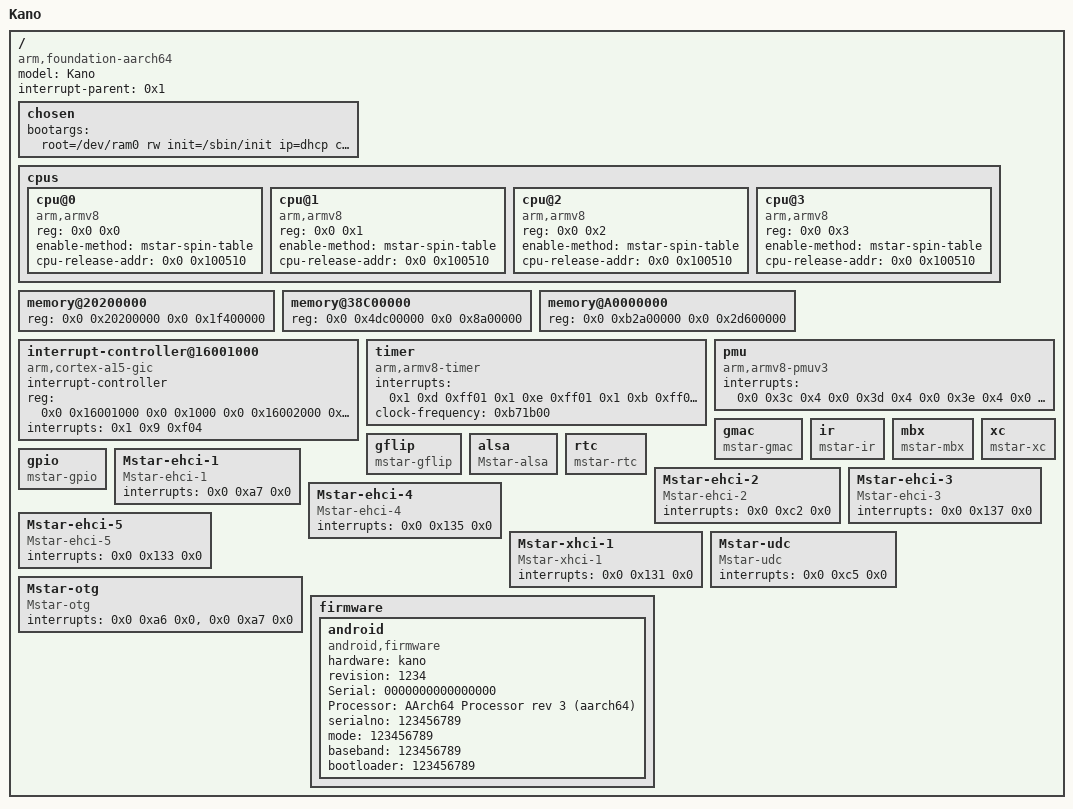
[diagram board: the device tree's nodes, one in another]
/dts-v1/;

/ {
	model = "Kano";
	compatible = "arm,foundation-aarch64", "arm,kano";
	interrupt-parent = <0x1>;
	#address-cells = <0x2>;
	#size-cells = <0x2>;

	chosen {
		bootargs = "root=/dev/ram0 rw init=/sbin/init ip=dhcp console=ttyS0,115200,LX_MEM=0x02000000 CMA0=mali0,miu=0,hid=16,sz=0x19000000 CMA1=mali1,miu=1,hid=17,sz=0x5400000 CORE_DUMP_PATH=/mnt/usb/core_dump.%%p.gz";
	};

	cpus {
		#address-cells = <0x2>;
		#size-cells = <0x0>;

		cpu@0 {
			device_type = "cpu";
			compatible = "arm,armv8";
			reg = <0x0 0x0>;
			enable-method = "mstar-spin-table";
			cpu-release-addr = <0x0 0x100510>;
		};

		cpu@1 {
			device_type = "cpu";
			compatible = "arm,armv8";
			reg = <0x0 0x1>;
			enable-method = "mstar-spin-table";
			cpu-release-addr = <0x0 0x100510>;
		};

		cpu@2 {
			device_type = "cpu";
			compatible = "arm,armv8";
			reg = <0x0 0x2>;
			enable-method = "mstar-spin-table";
			cpu-release-addr = <0x0 0x100510>;
		};

		cpu@3 {
			device_type = "cpu";
			compatible = "arm,armv8";
			reg = <0x0 0x3>;
			enable-method = "mstar-spin-table";
			cpu-release-addr = <0x0 0x100510>;
		};
	};

	memory@20200000 {
		device_type = "memory";
		reg = <0x0 0x20200000 0x0 0x1f400000>;
	};

	memory@38C00000 {
		device_type = "memory";
		reg = <0x0 0x4dc00000 0x0 0x8a00000>;
	};

	memory@A0000000 {
		device_type = "memory";
		reg = <0x0 0xb2a00000 0x0 0x2d600000>;
	};

	interrupt-controller@16001000 {
		compatible = "arm,cortex-a15-gic", "arm,cortex-a9-gic";
		#interrupt-cells = <0x3>;
		#address-cells = <0x0>;
		interrupt-controller;
		reg = <0x0 0x16001000 0x0 0x1000 0x0 0x16002000 0x0 0x4000>;
		interrupts = <0x1 0x9 0xf04>;
		linux,phandle = <0x1>;
		phandle = <0x1>;
	};

	timer {
		compatible = "arm,armv8-timer";
		interrupts = <0x1 0xd 0xff01 0x1 0xe 0xff01 0x1 0xb 0xff01 0x1 0xa 0xff01>;
		clock-frequency = <0xb71b00>;
	};

	pmu {
		compatible = "arm,armv8-pmuv3";
		interrupts = <0x0 0x3c 0x4 0x0 0x3d 0x4 0x0 0x3e 0x4 0x0 0x3f 0x4>;
	};

	gmac {
		compatible = "mstar-gmac";
	};

        ir {
	        compatible = "mstar-ir";	
	};
   
	mbx {
	        compatible = "mstar-mbx";	
	};
	
	xc {
		compatible = "mstar-xc";
	};
	
	gflip {
		compatible = "mstar-gflip";
	};

	alsa {
		compatible = "Mstar-alsa";
	};

	rtc {
	        compatible = "mstar-rtc";	
	};
	
	gpio {
        compatible = "mstar-gpio";
	};

	Mstar-ehci-1 {
		compatible = "Mstar-ehci-1";
		interrupts = <0x0 0xa7 0x0>;
	};

	Mstar-ehci-2 {
		compatible = "Mstar-ehci-2";
		interrupts = <0x0 0xc2 0x0>;
	};

	Mstar-ehci-3 {
		compatible = "Mstar-ehci-3";
		interrupts = <0x0 0x137 0x0>;
	};

	Mstar-ehci-4 {
		compatible = "Mstar-ehci-4";
		interrupts = <0x0 0x135 0x0>;
	};
	
	Mstar-ehci-5 {
		compatible = "Mstar-ehci-5";
		interrupts = <0x0 0x133 0x0>;
	};
	
        Mstar-xhci-1 {
                compatible = "Mstar-xhci-1";
		interrupts = <0x0 0x131 0x0>;
        };

  Mstar-udc {
  	compatible = "Mstar-udc";
  	interrupts = <0x0 0xc5 0x0>;   
  	};
  	
  Mstar-otg {
  	compatible = "Mstar-otg";
  	interrupts = <0x0 0xa6 0x0>, <0x0 0xa7 0x0>;   
  	};  	
  firmware {
		android {
			compatible = "android,firmware";
			hardware ="kano";
			revision ="1234";
			Serial   ="0000000000000000";
			Processor ="AArch64 Processor rev 3 (aarch64)";
			serialno ="123456789";
			mode ="123456789";
			baseband ="123456789";
			bootloader ="123456789";
		};
	};  	
};
